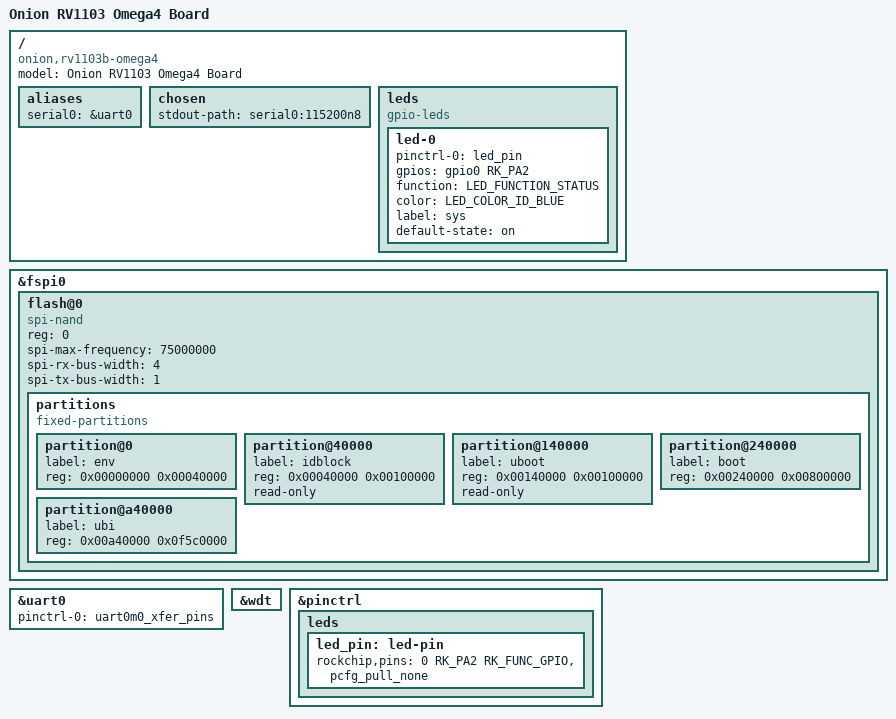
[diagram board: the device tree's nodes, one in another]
// SPDX-License-Identifier: (GPL-2.0+ OR MIT)
/*
 * Copyright (c) 2022 Rockchip Electronics Co., Ltd.
 * Copyright (c) 2025 plan44.ch/luz
 * Copyright (c) 2025 Onion Corporation
 */

/dts-v1/;

#include <dt-bindings/gpio/gpio.h>
#include <dt-bindings/leds/common.h>
#include "rv1103b.dtsi"

/ {
	model = "Onion RV1103 Omega4 Board";
	compatible = "onion,rv1103b-omega4", "rockchip,rv1103b";

	aliases {
		serial0 = &uart0;
	};

	chosen {
		stdout-path = "serial0:115200n8";
	};

	leds {
		compatible = "gpio-leds";

		led-0	{
			pinctrl-names = "default";
			pinctrl-0 = <&led_pin>;
			gpios = <&gpio0 RK_PA2 GPIO_ACTIVE_HIGH>;
			function = LED_FUNCTION_STATUS;
			color = <LED_COLOR_ID_BLUE>;
			label = "sys";
			default-state = "on";
		};
	};
};

&fspi0 {
	status = "okay";

	flash@0 {
		compatible = "spi-nand";
		reg = <0>;
		bootph-pre-ram;
		bootph-some-ram;
		spi-max-frequency = <75000000>;
		spi-rx-bus-width = <4>;
		spi-tx-bus-width = <1>;

		partitions {
			compatible = "fixed-partitions";
			#address-cells = <1>;
			#size-cells = <1>;

			partition@0 {
				label = "env";
				reg = <0x00000000 0x00040000>;
			};

			partition@40000 {
				label = "idblock";
				reg = <0x00040000 0x00100000>;
				read-only;
			};

			partition@140000 {
				label = "uboot";
				reg = <0x00140000 0x00100000>;
				read-only;
			};

			partition@240000 {
				label = "boot";
				reg = <0x00240000 0x00800000>;
			};

			partition@a40000 {
				label = "ubi";
				reg = <0x00a40000 0x0f5c0000>;
			};
		};
	};
};

&uart0 {
	pinctrl-names = "default";
	pinctrl-0 = <&uart0m0_xfer_pins>;
	bootph-all;
	status = "okay";
};

&wdt {
	bootph-all;
	status = "okay";
};

&pinctrl {
	leds {
		led_pin: led-pin {
			rockchip,pins = <0 RK_PA2 RK_FUNC_GPIO &pcfg_pull_none>;
		};
	};
};
